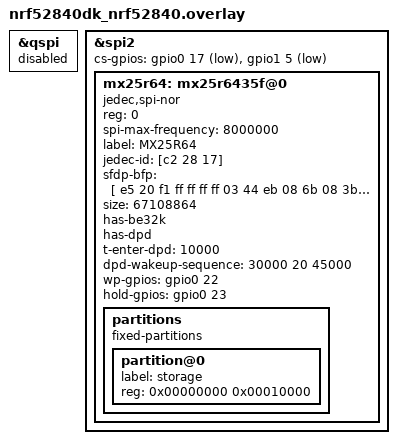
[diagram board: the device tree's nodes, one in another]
/*
 * Copyright (c) 2019 Peter Bigot Consulting, LLC
 *
 * SPDX-License-Identifier: Apache-2.0
 */

/delete-node/ &storage_partition;
/delete-node/ &mx25r64;

&qspi {
	status = "disabled";
};

&spi2 {
	status = "okay";
	cs-gpios = <&gpio0 17 GPIO_ACTIVE_LOW>, <&gpio1 5 GPIO_ACTIVE_LOW>;
	mx25r64: mx25r6435f@0 {
		status = "okay";
		compatible = "jedec,spi-nor";
		reg = <0>;
		spi-max-frequency = <8000000>;
		label = "MX25R64";
		jedec-id = [c2 28 17];
		sfdp-bfp = [
			e5 20 f1 ff  ff ff ff 03  44 eb 08 6b  08 3b 04 bb
			ee ff ff ff  ff ff 00 ff  ff ff 00 ff  0c 20 0f 52
			10 d8 00 ff  23 72 f5 00  82 ed 04 cc  44 83 68 44
			30 b0 30 b0  f7 c4 d5 5c  00 be 29 ff  f0 d0 ff ff
		];

		size = <67108864>;
		has-be32k;
		has-dpd;
		t-enter-dpd = <10000>;
		dpd-wakeup-sequence = <30000 20 45000>;
		wp-gpios = <&gpio0 22 0>;
		hold-gpios = <&gpio0 23 0>;
	};
};

&mx25r64 {
	partitions {
		compatible = "fixed-partitions";
		#address-cells = <1>;
		#size-cells = <1>;

		partition@0 {
			label = "storage";
			reg = <0x00000000 0x00010000>;
		};
	};
};
